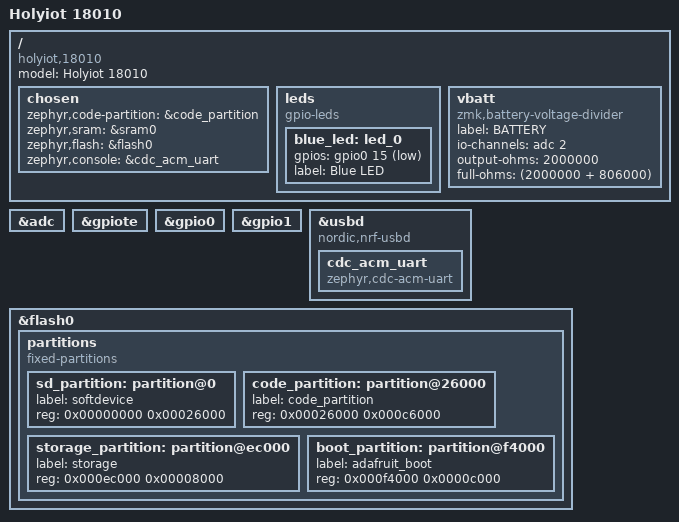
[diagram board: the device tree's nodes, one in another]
/dts-v1/;
#include <nordic/nrf52840_qiaa.dtsi>

/ {
	model = "Holyiot 18010";
	compatible = "holyiot,18010";

	chosen {
		zephyr,code-partition = &code_partition;
		zephyr,sram = &sram0;
		zephyr,flash = &flash0;
		zephyr,console = &cdc_acm_uart;
	};

	leds {
		compatible = "gpio-leds";
		blue_led: led_0 {
			gpios = <&gpio0 15 GPIO_ACTIVE_LOW>;
			label = "Blue LED";
		};
	};

	vbatt: vbatt {
		compatible = "zmk,battery-voltage-divider";
		label = "BATTERY";
		io-channels = <&adc 2>;
		output-ohms = <2000000>;
		full-ohms = <(2000000 + 806000)>;
	};
};

&adc {
	status = "okay";
};

&gpiote {
	status = "okay";
};

&gpio0 {
	status = "okay";
};

&gpio1 {
	status = "okay";
};

&usbd {
	compatible = "nordic,nrf-usbd";
	status = "okay";
	cdc_acm_uart: cdc_acm_uart {
		compatible = "zephyr,cdc-acm-uart";
	};
};

&flash0 {
	partitions {
		compatible = "fixed-partitions";
		#address-cells = <1>;
		#size-cells = <1>;

		sd_partition: partition@0 {
			label = "softdevice";
			reg = <0x00000000 0x00026000>;
		};
		code_partition: partition@26000 {
			label = "code_partition";
			reg = <0x00026000 0x000c6000>;
		};
		storage_partition: partition@ec000 {
			label = "storage";
			reg = <0x000ec000 0x00008000>;
		};
		boot_partition: partition@f4000 {
			label = "adafruit_boot";
			reg = <0x000f4000 0x0000c000>;
		};
	};
};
